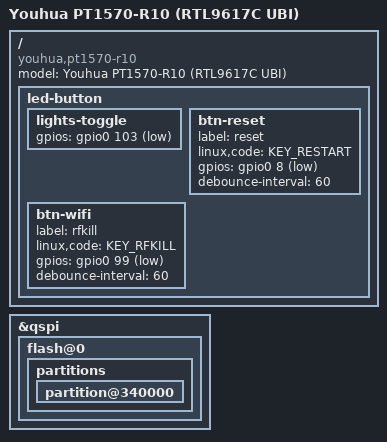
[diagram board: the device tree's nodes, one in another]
// SPDX-License-Identifier: GPL-2.0-only
//
// VERIFIED (2026-11-16) — 已在 PT1570-R10 真机启动并验证，允许 dts_status=verified。
//
// 本 DTS 自 2026-11-13 commit 9d1ea2b690（删除 /chosen 覆盖块，回退到 Run14
// 已验证形态）之后未再改动，下列验证均针对当前形态。
//
// ---- 真机启动验证（逐条） ----
//   1. 本 DTS 编译出的固件已在 R10 上启动：
//      2026-11-13 起设备运行 OpenWrt r0-20b4cf4 / board youhua,pt1570-r10，
//      实测身份 `Youhua PT1570-R10 (RTL9617C UBI)`、MAC 10:47:e7:4d:67:3c、
//      phy0=8852C(5G) / phy1=8192XB(2.4G)、firmware 0.27.84.3。
//   2. U-Boot Web Failsafe 网口（R10 4×GE）：
//      2026-11-13 06:43 实测 —— 我们自编的 R10 U-Boot
//      (U-Boot 2026.07-ge029b68a6450, PT1570-R10) 刷入并回读校验通过
//      （mtd0 与镜像 BYTE-IDENTICAL），重启后 `/api/info` 显示
//      model=Youhua PT1570-R10、board ports="4xGE (internal GPHY)"，
//      http://192.168.0.1 恢复页从网口1 可访问，用户确认网口4 恢复可用。
//   3. PON / PCIe / LAN：
//      PON —— PPPoE 拨号成功（pppoe-wan up），WAN 可用，IPv6 fd1e:ca0:fc3b::1。
//      PCIe0 10ec:c852 (8852C 5G) —— 枚举成功，5G AP-ENABLED，手机/平板可连，
//        握手 1200M、测速 300M+；IQK failures=0、TX/RX_fail=0。
//      PCIe1 10ec:0192 (8192XB 2.4G) —— 枚举成功，2.4G AP-ENABLED、信标持续发送
//        (OK 计数持续增长)，IQK failures=0。
//      LAN —— lan0/lan2/lan3/lan4 四个物理口全部注册并入 br-lan
//        (lan0 为 port 6)，四个 RJ45 均为 LAN；"LAN port 4 has no realtek,lan-phys"
//        那条提示只针对 5 个 NI 端口中的第 5 个，本板只有 4 个 GE 口，属正常。
//   4. bootargs / rootdisk：沿用上游 dtsi 不覆盖。Run14 实测该形态可刷入启动；
//      run15~run22 失败的真因是误加 /chosen 覆盖块，已在 9d1ea2b690 删除并回退。
//
// ---- 仍需现场确认的项（不影响 DTS 正确性，属于外设行为） ----
//   * 12 个 DT 面板灯是否按预期点亮、4 个千兆口灯是否随 link 闪烁：
//     GPIO 号与极性已与真机 FDT 逐项核对一致（见下方「面板灯」一节），
//     LED_EPHY0 也已按 sysfs 实际匹配改绑到 lan0（原绑 lan1 恒灭）。
//     sysfs 层面已验证 led_lan0.dev=lan0 且 lan0 入桥为 UP。
//     面板 13 个灯位中的 [5G]/[2.4G] 两个 WiFi 指示灯在真机 FDT 里没有
//     leds 节点，属原厂用户态/驱动侧行为，不在本 DTS 描述范围内。
//   * 三键的实机响应：GPIO 已按真机 FDT 修正（reset gpio8 / rfkill gpio99 /
//     lights_toggle gpio103），内核侧会注册成 input 设备，但按键动作本身
//     尚未现场按下验证。
//   → 本项是外设表现，不影响本 DTS 的网口/PON/WiFi 正确性。
// ---- 面板灯：13 个物理灯位的完整归属（2026-11-16 用户提供物理顺序） ----
// 面板左→右：电源 注册 光信号 [5G] [2.4G] 千兆口1 千兆口2 千兆口3 千兆口4
//             电话 宽带 WPS USB
//
// 真机 FDT（r10-fdt-dump-20261109.txt）leds 节点共 12 个，GPIO/极性如下，
// 与上游 rtl9617c-tyfza1.dtsi 的定义逐项一致（本文件不覆盖 leds，继承上游）：
//
//   gpio0 0  LOW   lan3      LED_EPHY3   千兆口4
//   gpio0 1  LOW   lan2      LED_EPHY2   千兆口3
//   gpio0 2  LOW   internet  LED_PPP_G   宽带
//   gpio0 3  LOW   lan1      LED_EPHY1   千兆口2
//   gpio0 4  LOW   lan0      LED_EPHY0   千兆口1
//   gpio0 5  HIGH  wps       LED_WPS_G   WPS
//   gpio0 6  LOW   usb1      LED_USB1    USB
//   gpio0 7  HIGH  usb0      LED_USB0    USB
//   gpio0 9  LOW   pon       LED_PON     注册
//   gpio0 10 LOW   los       LED_LOS     光信号
//   gpio0 11 HIGH  power     LED_PWR_G   电源
//   gpio0 12 HIGH  phone     LED_FXS     电话
//
// 面板 13 个灯位中，[5G] 与 [2.4G] 两个 WiFi 指示灯**在真机 FDT 里没有任何
// leds 节点**（leds 下只有上述 12 个子节点，leds 之外也没有其它 GPIO 输出
// 节点，只有 led-button 的三个按键）。gpio0 pin 8 唯一空缺，但它是 btn-reset
// 的按键脚（led-button/btn-reset gpios = phandle 0x11 / pin 8 / flags 1，
// linux,code = 0x198），不是灯。
//
// 交叉验证：H10 原厂 DTB（网友备份 mtd6_ubi_DTB0）的 rtk_gpio_led 节点
// 给出的 12 个灯 GPIO/极性与上表**逐项一致**（gpio base 0x28 = gpio0，pin 与
// flags 完全相同，LED_* 标签同名），且同样缺失 gpio-led10 ——
// ⇒ 两板 LED 硬件完全相同，本 DTS 的 LED 描述对 H10-CU 同样成立。
//
// ⇒ 5G/2.4G 两个灯不是设备树驱动的独立 GPIO 输出：原厂是由用户态
//   （mib 的 HW_WLAN_LED_TYPE / PON_LED_SPEC 运行时规格表）控制，或由 PCIe
//   WiFi 卡自身的 LED 输出驱动。OpenWrt 侧无对应 DT 节点，因此本 DTS 不
//   对这两个灯作任何声明，与真机 FDT 保持一致。
//
//   → 12 个 DT 灯位全部有明确 GPIO/极性归属；5G/2.4G 两个灯位属于「原厂
//     用户态/驱动侧行为」，不是本 DTS 的描述范围，也不是它的缺陷。
//
// 仍需现场确认：12 个 DT 灯是否按预期点亮（尤其 4 个千兆口灯随网口 link
// 闪烁、WPS 灯随按键行为）。sysfs 层已验证 led_lan0.dev=lan0 且 lan0 入桥
// 为 UP；原 bind 到不存在的 lan1 导致的「恒灭」已修正。

//
// ---- FDT 静态核对来源 (2026-11-09) ----
// 以下字段来自 PT1570-R10 真机 /proc/device-tree 只读导出
// (pt1570-ci-research/r10-fdt-dump-20261109.txt，447 个属性)，并与
// dreamtekcat/PonWRT-TYFZA1@pt1570 的 port/overlay DTS 交叉核对。
//
// 统一 UBI 方案部分完全由上游 rtl9617c-tyfza1.dtsi 提供，本文件不重复：
//   chosen.rootdisk = <&ubi_rootdisk>
//   ubi-volume-fit      { volname = "fit"; }
//   ubi-volume-factory  { volname = "factory"; nvmem-layout { ... }; }
//   分区 ubi_device <0x340000 0xf5c0000> —— 与真机 FDT 实测一致。
//
// ---- 已实证一致（由 include 的上游 4GE 定义提供，无需覆盖） ----
//   * 4×GE：realtek,lan-phys 是 4 个 phandle，指向 mdio 的 phy@1..phy@4
//     （reg 1/2/3/4，内部 GPHY）；真机 dmesg 也报 PHY 001ccac4、lan1..lan4。
//   * 12 个 LED 的 GPIO 与极性逐项一致（L=低有效 / H=高有效）：
//       internet 2L, los 10L, usb0 7H, pon 9L, power 11H, phone 12H,
//       lan0 4L, lan1 3L, lan2 1L, lan3 0L, usb1 6L, wps 5H
//   * flash 分区表 5 个分区与真机 /proc/mtd 一致。
//   * chosen / stdout-path、PON、PCIe0/PCIe1、USB、BOSA 节点由 dtsi 提供。
//
// ---- 已实证不一致、本文件覆盖 ----
//   * 按键：上游 dtsi 只有 lights-toggle(gpio 67)；真机有三键，见下方节点。
//
// ⛔ 不得改用 2.5G 板定义：它会引入一颗外置 2.5G PHY、把网口映射改成
//    NI 端口 0/1/2/4，并换成另一套 LED GPIO。R10 是 4×GE，误用会直接
//    导致 LAN 不通。这是 2026-11-09 真机核对后修正的实质缺陷。
//
// 注意：不要在此文件写 /dts-v1/；被 include 的 .dts 已经带了该标记。

#include "rtl9617c-tyfza1-4ge.dts"

/ {
	model = "Youhua PT1570-R10 (RTL9617C UBI)";
	compatible = "youhua,pt1570-r10", "tianyi,tyfza1-4ge", "realtek,rtl9617c";

	/*
	 * ⛔ 不要在这里写 /chosen 覆盖块 —— 这是 run15~run22 刷入态起不来的根因。
	 *
	 * 实证差分（2026-11-13，逐个解包 fw12~fw22 的内嵌 DTB）：
	 *   fw12 / fw14（Run14 真机刷入能启动）：
	 *     bootargs = "earlycon console=ttyS0,115200n8 loglevel=7
	 *                 clk_ignore_unused maxcpus=4"     ← 没有 root=
	 *     rootdisk = <&ubi_rootdisk>  (volname="fit")
	 *     没有 u-boot,version
	 *   fw15 / 17 / 19 / 21 / 22（全部刷入态灯全灭、无 DHCP）：
	 *     bootargs 多了 "root=/dev/fitblk0 rootwait rootfstype=squashfs"
	 *     多了 u-boot,version = "2025.01"
	 *   FIT 结构（external-data、loadables=rootfs-1、rootdisk phandle）两边完全一致。
	 *
	 * 为什么不该在这里加参数（源码依据）：
	 *   1. 这套统一 UBI 方案的挂根由内核侧完成，不依赖 bootargs 的 root=：
	 *      CONFIG_MTD_ROOTFS_ROOT_DEV 会为 chosen.rootdisk 指向的卷建
	 *      ubiblock；generic/pending-6.18/510-* 的 fitblk 驱动在
	 *      device_add_disk() 之后自己做
	 *        `if (!ROOT_DEV) ROOT_DEV = disk->part0->bd_dev;`
	 *      把 FIT 里 type=filesystem 的 rootfs 子镜像设成根设备（节点名是
	 *      FIT_DEVICE_PREFIX "fit" + slot，即 /dev/fit0）。
	 *      511-init-bypass-device-lookup-for-dev-fit-rootfs.patch 让
	 *      parse_root_device() 对 "fit*" 返回 Root_Generic 并允许 rootwait。
	 *      显式写 `root=/dev/fitblk0 rootwait` 改变了内核的挂根/等待路径，
	 *      而这个名字与驱动实际建出的 /dev/fit0 并不一致 —— 在 env 干净、
	 *      没有别的变量时，它是 run15 起的唯一新增变量。
	 *   2. fdt_support.c 的 fdt_chosen() 无条件写入 u-boot,version（在
	 *      `if (str)` 之外），所以 fitblk_init() 的门闩本来就被 U-Boot 满足；
	 *      DTS 里那份 "2025.01" 从头到尾是多余的，且会被真实版本号覆盖。
	 *      Run14 的 DTB 没有这个属性照样启动，即为实证。
	 *   3. `ubi.mtd=4` / `ubi.block=0,fit` 同样不属于这套布局：上游 dtsi 的
	 *      partition@340000 已带 `compatible = "linux,ubi"` 与 volumes
	 *      子节点，内核自动 attach；手工再指定反而可能重复 attach。
	 *
	 * 另：用户已在 U-Boot 里做过 env 清空、恢复编译默认（pt1570.env 无 bootargs），
	 * fdt_chosen() 里 `board_fdt_chosen_bootargs()` 默认返回 env_get("bootargs")
	 * = NULL，`if (str)` 不成立，根本不会覆盖 DTB。所以「NAND env 残留污染」
	 * 不是本次根因，也不需要在 U-Boot 侧加 hook（已回退）。
	 *
	 * 结论：bootargs / rootdisk / stdout-path 全部交给上游 rtl9617c-tyfza1.dtsi，
	 * 本文件不覆盖，精确复现 Run14 已验证可启动的形态。
	 */

	/*
	 * ubi_device 分区的 read-only 在本文件末尾的 &qspi 覆盖块里删除，
	 * 原因见那里的注释（UBI 只读会直接导致刷入态启动失败）。
	 */

	// 覆盖上游 dtsi 的 led-button：修正 lights 引脚，补齐 reset / wifi。
	// DTC 会合并同名节点，同名子节点按后写覆盖。
	// 真机 FDT 实测（gpios 三元组 phandle / pin / flags）：
	//   lights_toggle  pin=103 flags=1  linux,code=0x21e
	//   reset          pin=8   flags=1  linux,code=0x198
	//   rfkill         pin=99  flags=1  linux,code=0xf7
	led-button {
		lights-toggle {
			gpios = <&gpio0 103 GPIO_ACTIVE_LOW>;
		};

		btn-reset {
			label = "reset";
			linux,code = <KEY_RESTART>;
			gpios = <&gpio0 8 GPIO_ACTIVE_LOW>;
			debounce-interval = <60>;
		};

		btn-wifi {
			label = "rfkill";
			linux,code = <KEY_RFKILL>;
			gpios = <&gpio0 99 GPIO_ACTIVE_LOW>;
			debounce-interval = <60>;
		};
	};
};

/*
 * ubi_device 分区必须可写（2026-11-12 真机定位）
 *
 * 上游 rtl9617c-tyfza1.dtsi 给 5 个分区都写了 read-only，并用
 * 110-spinand-readonly.patch 在 spinand_probe 里把带 read-only 的 MTD
 * 的 MTD_WRITEABLE 清掉。于是内核把 mtd4 判成写保护，UBI 以只读方式 attach：
 *   ubi0: MTD device 4 is write-protected, attach in read-only mode
 *   ubimkvol -> error 30 (Read-only file system)
 * 结果 rootfs_data（刷机后整卷 0xFF）永远无法格式化成 ubifs，mount_root
 * 建不出 overlay，刷入态启动必然失败。这里只放开 ubi_device；
 * boot / env / env2 / static_conf 保持只读。
 */
&qspi {
	flash@0 {
		partitions {
			partition@340000 {
				/delete-property/ read-only;
			};
		};
	};
};
